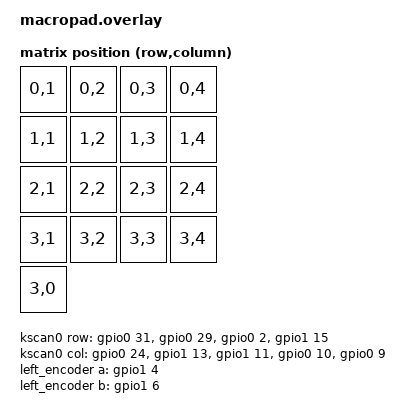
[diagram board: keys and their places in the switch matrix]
// This file was generated from a template. Edit it to match your keyboard.
// See https://zmk.dev/docs/development/hardware-integration/new-shield for more
// instructions.

#include <dt-bindings/zmk/matrix_transform.h>

#include "macropad-layouts.dtsi"

/ {
    chosen {
        zmk,kscan = &kscan0;
        zmk,matrix-transform = &default_transform;
    };

    /* Definisi Matrix Scanning GPIO (4 Rows x 5 Cols) */
    kscan0: kscan {
    compatible = "zmk,kscan-gpio-matrix";
    wakeup-source;
    diode-direction = "col2row";  // Changed from "COL2ROW"
    
    row-gpios
        = <&gpio0 31 (GPIO_ACTIVE_HIGH | GPIO_PULL_DOWN)>  // Row 0 - D21 (P0.31)
        , <&gpio0 29 (GPIO_ACTIVE_HIGH | GPIO_PULL_DOWN)>  // Row 1 - D20 (P0.29)
        , <&gpio0 2 (GPIO_ACTIVE_HIGH | GPIO_PULL_DOWN)>   // Row 2 - D19 (P0.02)
        , <&gpio1 15 (GPIO_ACTIVE_HIGH | GPIO_PULL_DOWN)>  // Row 3 - D18 (P1.15)
        ;
    
    col-gpios
        = <&gpio0 24 GPIO_ACTIVE_HIGH>  // Col 0 - D5 (Encoder button)
        , <&gpio1 13 GPIO_ACTIVE_HIGH>   // Col 1 - D15 (P1.13)
        , <&gpio1 11 GPIO_ACTIVE_HIGH>  // Col 2 - D14 (P1.11)
        , <&gpio0 10 GPIO_ACTIVE_HIGH>   // Col 3 - D16 (P0.10)
        , <&gpio0 9 GPIO_ACTIVE_HIGH>   // Col 4 - D10 (P0.09)
        ;
    };

    /* Matrix Transform untuk memetakan tombol di ZMK Keymap */
    default_transform: matrix_transform {
    compatible = "zmk,matrix-transform";
    rows = <4>;
    columns = <5>;
    map = <
        RC(0,1) RC(0,2) RC(0,3) RC(0,4)
        RC(1,1) RC(1,2) RC(1,3) RC(1,4)
        RC(2,1) RC(2,2) RC(2,3) RC(2,4)
        RC(3,1) RC(3,2) RC(3,3) RC(3,4)
        RC(3,0)                          // Encoder button as separate key
    >;
};

    /* Definisi Hardware Rotary Encoder (Sisi Kiri Kiri-Bawah / Posisi X) */
    left_encoder: encoder_left {
        compatible = "alps,ec11";
        a-gpios = <&gpio1 4 (GPIO_ACTIVE_HIGH | GPIO_PULL_UP)>;  // Pin A (D8) 
        b-gpios = <&gpio1 6 (GPIO_ACTIVE_HIGH | GPIO_PULL_UP)>;  // Pin B (D9)
        steps = <80>;
        status = "okay";
    };

    sensors: sensors {
        compatible = "zmk,keymap-sensors";
        sensors = <&left_encoder>;
        triggers-per-rotation = <20>;
    };
};
